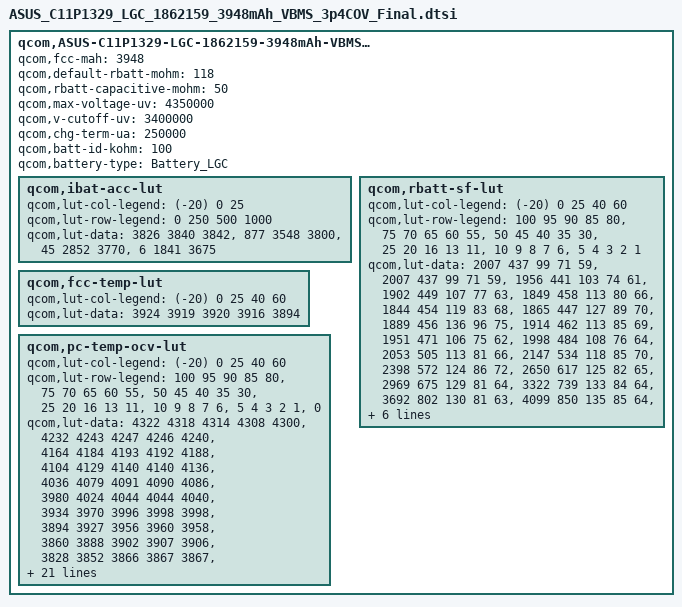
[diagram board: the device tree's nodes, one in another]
 qcom,ASUS-C11P1329-LGC-1862159-3948mAh-VBMS-data {
	qcom,fcc-mah = <3948>;
	qcom,default-rbatt-mohm = <118>;
	qcom,rbatt-capacitive-mohm = <50>;
	qcom,max-voltage-uv = <4350000>;
	qcom,v-cutoff-uv = <3400000>;
	qcom,chg-term-ua = <250000>;
	qcom,batt-id-kohm = <100>;
	qcom,battery-type = "Battery_LGC";

	qcom,ibat-acc-lut {
		qcom,lut-col-legend = <(-20) 0 25>;
		qcom,lut-row-legend = <0 250 500 1000>;
		qcom,lut-data = <3826 3840 3842>,
				<877 3548 3800>,
				<45 2852 3770>,
				<6 1841 3675>;
	};

	qcom,rbatt-sf-lut {
		qcom,lut-col-legend = <(-20) 0 25 40 60>;
		qcom,lut-row-legend = <100 95 90 85 80>,
				<75 70 65 60 55>,
				<50 45 40 35 30>,
				<25 20 16 13 11>,
				<10 9 8 7 6>,
				<5 4 3 2 1>;
		qcom,lut-data = <2007 437 99 71 59>,
				<2007 437 99 71 59>,
				<1956 441 103 74 61>,
				<1902 449 107 77 63>,
				<1849 458 113 80 66>,
				<1844 454 119 83 68>,
				<1865 447 127 89 70>,
				<1889 456 136 96 75>,
				<1914 462 113 85 69>,
				<1951 471 106 75 62>,
				<1998 484 108 76 64>,
				<2053 505 113 81 66>,
				<2147 534 118 85 70>,
				<2398 572 124 86 72>,
				<2650 617 125 82 65>,
				<2969 675 129 81 64>,
				<3322 739 133 84 64>,
				<3692 802 130 81 63>,
				<4099 850 135 85 64>,
				<4444 879 145 90 68>,
				<4505 876 150 93 69>,
				<4585 861 156 95 70>,
				<4907 885 162 97 70>,
				<5302 908 165 97 66>,
				<5741 934 161 92 66>,
				<6308 962 157 90 68>,
				<7093 995 161 94 69>,
				<8155 1037 169 99 73>,
				<9849 1099 186 109 82>,
				<13548 1544 273 161 109>;
	};

	qcom,fcc-temp-lut {
		qcom,lut-col-legend = <(-20) 0 25 40 60>;
		qcom,lut-data = <3924 3919 3920 3916 3894>;
	};

	qcom,pc-temp-ocv-lut {
		qcom,lut-col-legend = <(-20) 0 25 40 60>;
		qcom,lut-row-legend = <100 95 90 85 80>,
				<75 70 65 60 55>,
				<50 45 40 35 30>,
				<25 20 16 13 11>,
				<10 9 8 7 6>,
				<5 4 3 2 1>,
				<0>;
		qcom,lut-data = <4322 4318 4314 4308 4300>,
				<4232 4243 4247 4246 4240>,
				<4164 4184 4193 4192 4188>,
				<4104 4129 4140 4140 4136>,
				<4036 4079 4091 4090 4086>,
				<3980 4024 4044 4044 4040>,
				<3934 3970 3996 3998 3998>,
				<3894 3927 3956 3960 3958>,
				<3860 3888 3902 3907 3906>,
				<3828 3852 3866 3867 3867>,
				<3799 3822 3838 3840 3840>,
				<3772 3799 3816 3818 3818>,
				<3746 3779 3796 3798 3798>,
				<3722 3764 3780 3781 3782>,
				<3700 3750 3766 3764 3754>,
				<3678 3737 3750 3744 3732>,
				<3656 3721 3726 3720 3707>,
				<3633 3704 3696 3688 3678>,
				<3612 3688 3684 3678 3666>,
				<3596 3677 3680 3675 3664>,
				<3588 3670 3680 3674 3664>,
				<3580 3664 3677 3672 3662>,
				<3568 3655 3674 3669 3658>,
				<3554 3642 3666 3661 3646>,
				<3538 3624 3646 3638 3618>,
				<3514 3596 3608 3598 3576>,
				<3483 3556 3556 3546 3528>,
				<3436 3498 3488 3480 3463>,
				<3368 3414 3398 3392 3378>,
				<3247 3276 3267 3266 3251>,
				<3000 3000 3000 3000 3000>;
	};
};
